# test register map
Vendor: Infineon; Series: RISCV; File version: 0.1
Example for regmock test and demonstration purposes
Address unit: 32 bits
Registers are 32-bit, read-write, reset 0x0 unless marked. A register's access mark holds for its fields unless they carry their own. Offsets are from the block's base; lines under a group give offsets from that group; [hi:lo] are bit positions; {n}, {i} and the like mark numbered series; 'fields as' and 'values as' point back to an identical list; <NAME> marks a mode.

## Memory map
0x00008000 timer size 0x18 — Timer Peripheral
0x00008200 spi size 0x10 — SPI Slave peripheral
0x00008400 gpio size 0x34

## Interrupts
0 timer0 (timer)
1 timer1 (timer)

## timer — Timer Peripheral
Base 0x00008000
{0x0+0xC*i} timercluster{i} (i=0..1) group
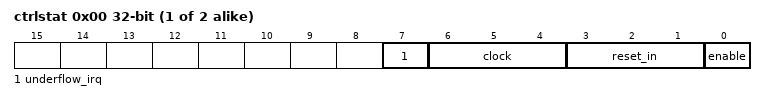
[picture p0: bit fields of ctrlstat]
  0x00 ctrlstat
    [7] underflow_irq — If set, an interrupt will be triggered if an underflow occurs
    [6:4] clock — Select external clock source
    [3:1] reset_in — Asynchronous signals get synchronized with the Timer/Counter clock
    [0] enable — Enable Timer / Counter
  0x04 count
    [31:0] value — The count register stores the actual counter value
  0x08 max
    [31:0] value — The max register contains the maximal value of the counter (count). On a Timer/Counter reset this value is copied into count.

## gpio
Base 0x00008400
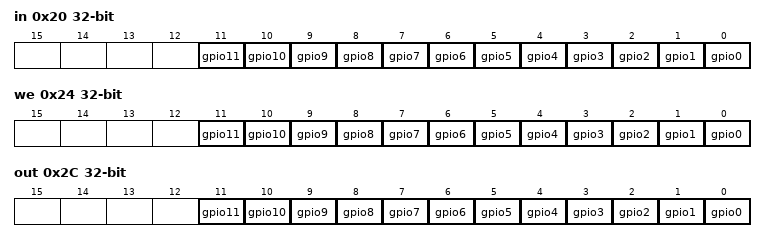
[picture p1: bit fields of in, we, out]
0x20 in ro
  [n] gpio{n} (n=0..11) — Level of GPIO{n}
0x24 we
  [all] fields
    0=in; 1=out
  [n] gpio{n} (n=0..11) — Direction of GPIO{n}
0x2C out
  [n] gpio{n} (n=0..11) — Level to drive on GPIO{n} if selected and enabled

## spi — SPI Slave peripheral
Base 0x00008200
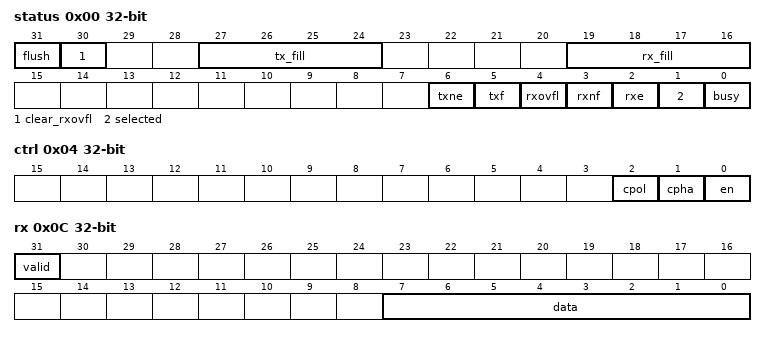
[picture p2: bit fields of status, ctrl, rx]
0x00 status reset not defined
  [31] flush wo write-1-clears — Write 1 to empty TX and RX FIFO
  [30] clear_rxovfl wo write-1-clears — Write 1 to clear the rxovfl bit
  [27:24] tx_fill ro — Number of bytes to be sent from the TX FIFO
  [19:16] rx_fill ro — Number of bytes to be read from the RX FIFO
  [6] txne ro — The TX FIFO is not empty
  [5] txf ro — The TX FIFO is full
  [4] rxovfl ro — The RX FIFO overflowed since the last clear
  [3] rxnf ro — The RX FIFO is not full
  [2] rxe ro — The RX FIFO is empty
  [1] selected ro — The device is selected via CS
  [0] busy ro — A byte is being transmitted
0x04 ctrl — Control register
  [2] cpol — Clock idle polarity
  [1] cpha — 0 to latch on first edge, 1 to shift
    0=firstLatches (The first edge of the clock latches data, first bit is driven from CS); 1=firstShifts (The first edge shifts data, CS assertion does not change data output)
  [0] en — Global module enable
0x08 tx reset not defined — Transmit FIFO
  [7:0] data wo — Write to TX FIFO
0x0C rx reset not defined — Receive FIFO
  [31] valid ro — A byte was available when the read occured
  [7:0] data ro read-has-side-effects — Read data from RX FIFO

## Licence text in the file
CC0 1.0 Universal CREATIVE COMMONS CORPORATION IS NOT A LAW FIRM AND DOES NOT PROVIDE LEGAL SERVICES. DISTRIBUTION OF THIS DOCUMENT DOES NOT CREATE AN ATTORNEY-CLIENT RELATIONSHIP. CREATIVE COMMONS PROVIDES THIS INFORMATION ON AN "AS-IS" BASIS. CREATIVE COMMONS MAKES NO WARRANTIES REGARDING THE USE OF THIS DOCUMENT OR THE INFORMATION OR WORKS PROVIDED HEREUNDER, AND DISCLAIMS LIABILITY FOR DAMAGES RESULTING FROM THE USE OF THIS DOCUMENT OR THE INFORMATION OR WORKS PROVIDED HEREUNDER.
